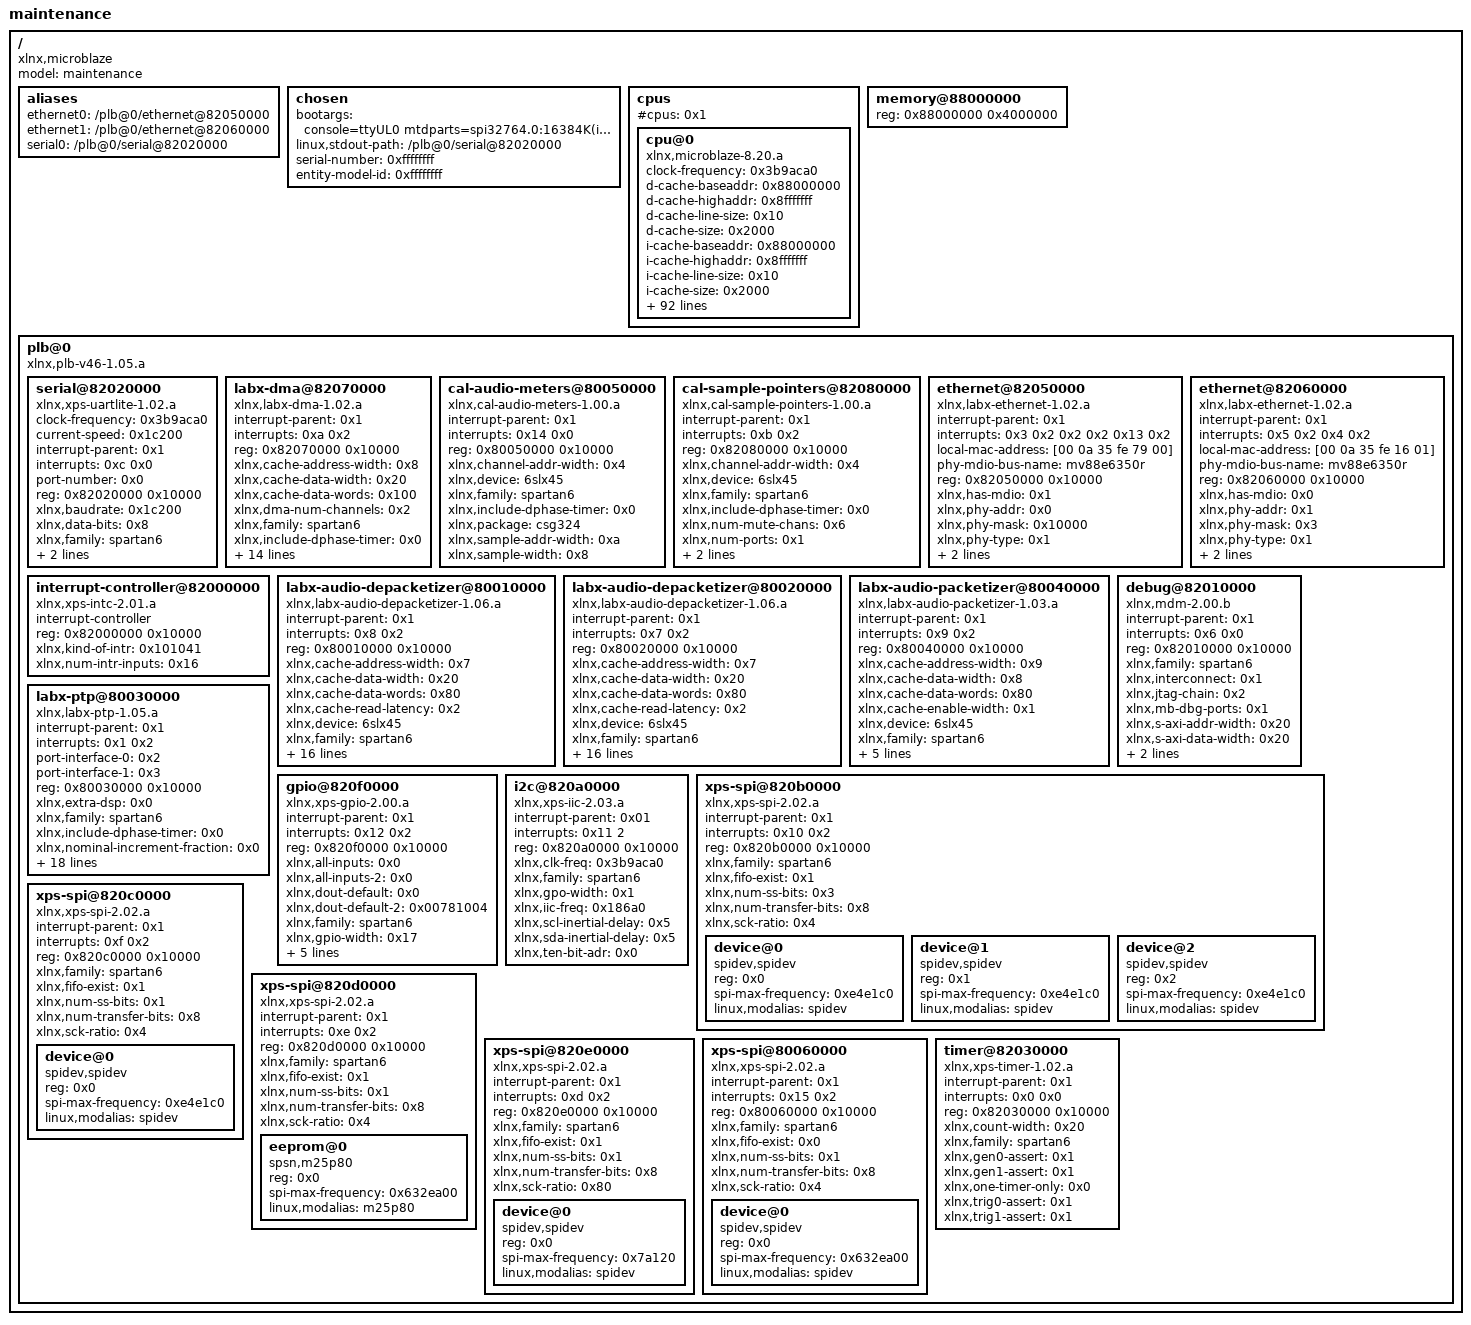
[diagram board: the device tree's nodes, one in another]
/dts-v1/;

/ {
	#address-cells = <0x1>;
	#size-cells = <0x1>;
	compatible = "xlnx,microblaze";
	model = "maintenance";

	aliases {
		ethernet0 = "/plb@0/ethernet@82050000";
		ethernet1 = "/plb@0/ethernet@82060000";
		serial0 = "/plb@0/serial@82020000";
	};

	chosen {
		bootargs = "console=ttyUL0 mtdparts=spi32764.0:16384K(image) root=/dev/ram0 load_ramdisk=1 ramdisk_start=4096 prompt_ramdisk=0 BUTTONS=0x00";
/*
		bootargs = "console=ttyUL0 mtdparts=spi32764.0:2048K(maintfpga),256K(maintboot),256K(maintfdt),1536K(maintimage),1024K(maintrootfs),768K(maintromfs),2048K(maintsettingsfs),256K(bootenv),2048K(fpga),256K(boot),256K(fdt),1536K(image),1024K(rootfs),1024K(romfs),2048K(settingsfs) root=mtd4 rootfstype=romfs init=/bin/init";
*/
		linux,stdout-path = "/plb@0/serial@82020000";
		serial-number=<0xffffffff>;
		entity-model-id=<0xffffffff>;
	};

	cpus {
		#address-cells = <0x1>;
		#cpus = <0x1>;
		#size-cells = <0x0>;

		cpu@0 {
			clock-frequency = <0x3b9aca0>;
			compatible = "xlnx,microblaze-8.20.a";
			d-cache-baseaddr = <0x88000000>;
			d-cache-highaddr = <0x8fffffff>;
			d-cache-line-size = <0x10>;
			d-cache-size = <0x2000>;
			device_type = "cpu";
			i-cache-baseaddr = <0x88000000>;
			i-cache-highaddr = <0x8fffffff>;
			i-cache-line-size = <0x10>;
			i-cache-size = <0x2000>;
			model = "microblaze,8.20.a";
			reg = <0x0>;
			timebase-frequency = <0x3b9aca0>;
			xlnx,addr-tag-bits = <0xe>;
			xlnx,allow-dcache-wr = <0x1>;
			xlnx,allow-icache-wr = <0x1>;
			xlnx,archiver = [30 00];
			xlnx,area-optimized = <0x0>;
			xlnx,avoid-primitives = <0x0>;
			xlnx,branch-target-cache-size = <0x0>;
			xlnx,cache-byte-size = <0x2000>;
			xlnx,compiler = [30 00];
			xlnx,compiler-flags = [30 00];
			xlnx,core-clock-freq-hz = <0x5f5e100>;
			xlnx,d-axi = <0x0>;
			xlnx,d-lmb = <0x1>;
			xlnx,d-plb = <0x1>;
			xlnx,data-size = <0x20>;
			xlnx,dcache-addr-tag = <0xe>;
			xlnx,dcache-always-used = <0x1>;
			xlnx,dcache-byte-size = <0x2000>;
			xlnx,dcache-data-width = <0x0>;
			xlnx,dcache-force-tag-lutram = <0x0>;
			xlnx,dcache-interface = <0x0>;
			xlnx,dcache-line-len = <0x4>;
			xlnx,dcache-use-fsl = <0x1>;
			xlnx,dcache-use-writeback = <0x0>;
			xlnx,dcache-victims = <0x0>;
			xlnx,debug-enabled = <0x1>;
			xlnx,div-zero-exception = <0x1>;
			xlnx,dynamic-bus-sizing = <0x1>;
			xlnx,ecc-use-ce-exception = <0x0>;
			xlnx,edge-is-positive = <0x1>;
			xlnx,endianness = <0x0>;
			xlnx,extra-compiler-flags = [30 00];
			xlnx,family = "spartan6";
			xlnx,fault-tolerant = <0x0>;
			xlnx,fpu-exception = <0x0>;
			xlnx,freq = <0x3b9aca0>;
			xlnx,fsl-data-size = <0x20>;
			xlnx,fsl-exception = <0x0>;
			xlnx,fsl-links = <0x1>;
			xlnx,i-axi = <0x0>;
			xlnx,i-lmb = <0x1>;
			xlnx,i-plb = <0x1>;
			xlnx,icache-always-used = <0x1>;
			xlnx,icache-data-width = <0x0>;
			xlnx,icache-force-tag-lutram = <0x0>;
			xlnx,icache-interface = <0x0>;
			xlnx,icache-line-len = <0x4>;
			xlnx,icache-streams = <0x0>;
			xlnx,icache-use-fsl = <0x1>;
			xlnx,icache-victims = <0x0>;
			xlnx,ill-opcode-exception = <0x1>;
			xlnx,instance = "microblaze_0";
			xlnx,interconnect = <0x1>;
			xlnx,interrupt-is-edge = <0x0>;
			xlnx,lockstep-slave = <0x0>;
			xlnx,mmu-dtlb-size = <0x4>;
			xlnx,mmu-itlb-size = <0x2>;
			xlnx,mmu-privileged-instr = <0x0>;
			xlnx,mmu-tlb-access = <0x3>;
			xlnx,mmu-zones = <0x10>;
			xlnx,multiplier = "false";
			xlnx,number-of-pc-brk = <0x1>;
			xlnx,number-of-rd-addr-brk = <0x0>;
			xlnx,number-of-wr-addr-brk = <0x0>;
			xlnx,opcode-0x0-illegal = <0x1>;
			xlnx,optimization = <0x0>;
			xlnx,pvr = <0x0>;
			xlnx,pvr-user1 = <0x0>;
			xlnx,pvr-user2 = <0x0>;
			xlnx,reset-msr = <0x0>;
			xlnx,sco = <0x0>;
			xlnx,stream-interconnect = <0x0>;
			xlnx,unaligned-exceptions = <0x1>;
			xlnx,use-barrel = <0x1>;
			xlnx,use-branch-target-cache = <0x0>;
			xlnx,use-dcache = <0x1>;
			xlnx,use-div = <0x1>;
			xlnx,use-ext-brk = <0x1>;
			xlnx,use-ext-nm-brk = <0x1>;
			xlnx,use-extended-fsl-instr = <0x0>;
			xlnx,use-fpu = <0x0>;
			xlnx,use-hw-mul = <0x1>;
			xlnx,use-icache = <0x1>;
			xlnx,use-interrupt = <0x1>;
			xlnx,use-mmu = <0x0>;
			xlnx,use-msr-instr = <0x1>;
			xlnx,use-pcmp-instr = <0x1>;
			xlnx,use-stack-protection = <0x0>;
			xlnx,xmdstub-peripheral = "false";
		};
	};

	memory@88000000 {
		device_type = "memory";
		reg = <0x88000000 0x4000000>;
	};

	plb@0 {
		#address-cells = <0x1>;
		#size-cells = <0x1>;
		compatible = "xlnx,plb-v46-1.05.a", "xlnx,plb-v46-1.00.a", "simple-bus";
		ranges;

		serial@82020000 {
			clock-frequency = <0x3b9aca0>;
			compatible = "xlnx,xps-uartlite-1.02.a", "xlnx,xps-uartlite-1.00.a";
			current-speed = <0x1c200>;
			device_type = "serial";
			interrupt-parent = <0x1>;
			interrupts = <0xc 0x0>;
			port-number = <0x0>;
			reg = <0x82020000 0x10000>;
			xlnx,baudrate = <0x1c200>;
			xlnx,data-bits = <0x8>;
			xlnx,family = "spartan6";
			xlnx,odd-parity = <0x1>;
			xlnx,use-parity = <0x0>;
		};

		labx-dma@82070000 {
			compatible = "xlnx,labx-dma-1.02.a";
			interrupt-parent = <0x1>;
			interrupts = <0xa 0x2>;
			reg = <0x82070000 0x10000>;
			xlnx,cache-address-width = <0x8>;
			xlnx,cache-data-width = <0x20>;
			xlnx,cache-data-words = <0x100>;
			xlnx,dma-num-channels = <0x2>;
			xlnx,family = "spartan6";
			xlnx,include-dphase-timer = <0x0>;
			xlnx,interface-type = "DMA_NPI";
			xlnx,internal-params = <0x1>;
			xlnx,microcode-words = <0x400>;
			xlnx,mplb-awidth = <0x20>;
			xlnx,mplb-clk-period-ps = <0x2710>;
			xlnx,mplb-dwidth = <0x80>;
			xlnx,mplb-native-dwidth = <0x20>;
			xlnx,mplb-p2p = <0x0>;
			xlnx,mplb-smallest-slave = <0x20>;
			xlnx,num-cache-interfaces = <0x2>;
			xlnx,num-param-interfaces = <0x2>;
			xlnx,param-address-width = <0x9>;
			xlnx,param-words = <0x200>;
			xlnx,parameter-interlock-fifo = <0x1>;
		};

		cal-audio-meters@80050000 {
			compatible = "xlnx,cal-audio-meters-1.00.a";
			interrupt-parent = <0x1>;
			interrupts = <0x14 0x0>;
			reg = <0x80050000 0x10000>;
			xlnx,channel-addr-width = <0x4>;
			xlnx,device = "6slx45";
			xlnx,family = "spartan6";
			xlnx,include-dphase-timer = <0x0>;
			xlnx,package = "csg324";
			xlnx,sample-addr-width = <0xa>;
			xlnx,sample-width = <0x8>;
		};

		cal-sample-pointers@82080000 {
			compatible = "xlnx,cal-sample-pointers-1.00.a";
			interrupt-parent = <0x1>;
			interrupts = <0xb 0x2>;
			reg = <0x82080000 0x10000>;
			xlnx,channel-addr-width = <0x4>;
			xlnx,device = "6slx45";
			xlnx,family = "spartan6";
			xlnx,include-dphase-timer = <0x0>;
			xlnx,num-mute-chans = <0x6>;
			xlnx,num-ports = <0x1>;
			xlnx,package = "csg324";
			xlnx,sample-addr-width = <0x8>;
		};

		ethernet@82050000 {
			compatible = "xlnx,labx-ethernet-1.02.a";
			device_type = "network";
			interrupt-parent = <0x1>;
			interrupts = <0x3 0x2 0x2 0x2 0x13 0x2>;
			local-mac-address = [00 0a 35 fe 79 00];
			phy-mdio-bus-name = "mv88e6350r";
			reg = <0x82050000 0x10000>;
			xlnx,has-mdio = <0x1>;
			xlnx,phy-addr = <0x0>;
			xlnx,phy-mask = <0x10000>;
			xlnx,phy-type = <0x1>;
			xlnx,rxcsum = <0x0>;
			xlnx,txcsum = <0x0>;
			linux,phandle = <0x2>;
		};

		ethernet@82060000 {
			compatible = "xlnx,labx-ethernet-1.02.a";
			device_type = "network";
			interrupt-parent = <0x1>;
			interrupts = <0x5 0x2 0x4 0x2>;
			local-mac-address = [00 0a 35 fe 16 01];
			phy-mdio-bus-name = "mv88e6350r";
			reg = <0x82060000 0x10000>;
			xlnx,has-mdio = <0x0>;
			xlnx,phy-addr = <0x1>;
			xlnx,phy-mask = <0x3>;
			xlnx,phy-type = <0x1>;
			xlnx,rxcsum = <0x0>;
			xlnx,txcsum = <0x0>;
			linux,phandle = <0x3>;
		};

		interrupt-controller@82000000 {
			#interrupt-cells = <0x2>;
			compatible = "xlnx,xps-intc-2.01.a", "xlnx,xps-intc-1.00.a";
			interrupt-controller;
			reg = <0x82000000 0x10000>;
			xlnx,kind-of-intr = <0x101041>;
			xlnx,num-intr-inputs = <0x16>;
			linux,phandle = <0x1>;
		};

		labx-audio-depacketizer@80010000 {
			compatible = "xlnx,labx-audio-depacketizer-1.06.a";
			interrupt-parent = <0x1>;
			interrupts = <0x8 0x2>;
			reg = <0x80010000 0x10000>;
			xlnx,cache-address-width = <0x7>;
			xlnx,cache-data-width = <0x20>;
			xlnx,cache-data-words = <0x80>;
			xlnx,cache-read-latency = <0x2>;
			xlnx,device = "6slx45";
			xlnx,family = "spartan6";
			xlnx,has-suppress-inputs = <0x0>;
			xlnx,include-dphase-timer = <0x0>;
			xlnx,interface-type = "CACHE_RAM";
			xlnx,is-mcr-host = <0x1>;
			xlnx,mcb-data-width = <0x20>;
			xlnx,mplb-awidth = <0x20>;
			xlnx,mplb-clk-period-ps = <0x2710>;
			xlnx,mplb-dwidth = <0x80>;
			xlnx,mplb-native-dwidth = <0x20>;
			xlnx,mplb-p2p = <0x0>;
			xlnx,mplb-smallest-slave = <0x20>;
			xlnx,npi-data-width = <0x20>;
			xlnx,num-clock-domains = <0x1>;
			xlnx,num-streams = <0x4>;
			xlnx,package = "csg324";
			xlnx,param-address-width = <0x9>;
		};

		labx-audio-depacketizer@80020000 {
			compatible = "xlnx,labx-audio-depacketizer-1.06.a";
			interrupt-parent = <0x1>;
			interrupts = <0x7 0x2>;
			reg = <0x80020000 0x10000>;
			xlnx,cache-address-width = <0x7>;
			xlnx,cache-data-width = <0x20>;
			xlnx,cache-data-words = <0x80>;
			xlnx,cache-read-latency = <0x2>;
			xlnx,device = "6slx45";
			xlnx,family = "spartan6";
			xlnx,has-suppress-inputs = <0x0>;
			xlnx,include-dphase-timer = <0x0>;
			xlnx,interface-type = "CACHE_RAM";
			xlnx,is-mcr-host = <0x1>;
			xlnx,mcb-data-width = <0x20>;
			xlnx,mplb-awidth = <0x20>;
			xlnx,mplb-clk-period-ps = <0x2710>;
			xlnx,mplb-dwidth = <0x80>;
			xlnx,mplb-native-dwidth = <0x20>;
			xlnx,mplb-p2p = <0x0>;
			xlnx,mplb-smallest-slave = <0x20>;
			xlnx,npi-data-width = <0x20>;
			xlnx,num-clock-domains = <0x1>;
			xlnx,num-streams = <0x4>;
			xlnx,package = "csg324";
			xlnx,param-address-width = <0x9>;
		};

		labx-audio-packetizer@80040000 {
			compatible = "xlnx,labx-audio-packetizer-1.03.a";
			interrupt-parent = <0x1>;
			interrupts = <0x9 0x2>;
			reg = <0x80040000 0x10000>;
			xlnx,cache-address-width = <0x9>;
			xlnx,cache-data-width = <0x8>;
			xlnx,cache-data-words = <0x80>;
			xlnx,cache-enable-width = <0x1>;
			xlnx,device = "6slx45";
			xlnx,family = "spartan6";
			xlnx,has-internal-cache-ram = <0x1>;
			xlnx,include-dphase-timer = <0x0>;
			xlnx,is-dual-headed = <0x1>;
			xlnx,num-clock-domains = <0x1>;
			xlnx,package = "csg324";
		};

		debug@82010000 {
			compatible = "xlnx,mdm-2.00.b";
			interrupt-parent = <0x1>;
			interrupts = <0x6 0x0>;
			reg = <0x82010000 0x10000>;
			xlnx,family = "spartan6";
			xlnx,interconnect = <0x1>;
			xlnx,jtag-chain = <0x2>;
			xlnx,mb-dbg-ports = <0x1>;
			xlnx,s-axi-addr-width = <0x20>;
			xlnx,s-axi-data-width = <0x20>;
			xlnx,s-axi-protocol = "AXI4LITE";
			xlnx,use-uart = <0x1>;
		};

		labx-ptp@80030000 {
			compatible = "xlnx,labx-ptp-1.05.a";
			interrupt-parent = <0x1>;
			interrupts = <0x1 0x2>;
			port-interface-0 = <0x2>;
			port-interface-1 = <0x3>;
			reg = <0x80030000 0x10000>;
			xlnx,extra-dsp = <0x0>;
			xlnx,family = "spartan6";
			xlnx,include-dphase-timer = <0x0>;
			xlnx,nominal-increment-fraction = <0x0>;
			xlnx,nominal-increment-mantissa = <0x8>;
			xlnx,num-ports = <0x2>;
			xlnx,phy-mac-rx-delay = <0x500>;
			xlnx,phy-mac-tx-delay = <0x500>;
			xlnx,port-interface-0 = "eth0";
			xlnx,port-interface-1 = "eth1";
			xlnx,port-interface-2 = "Invalid";
			xlnx,port-interface-3 = "Invalid";
			xlnx,port-interface-4 = "Invalid";
			xlnx,port-interface-5 = "Invalid";
			xlnx,port-interface-6 = "Invalid";
			xlnx,port-interface-7 = "Invalid";
			xlnx,port-width = <0x8>;
			xlnx,rtc-d-coefficient = <0x0>;
			xlnx,rtc-i-coefficient = <0x0>;
			xlnx,rtc-p-coefficient = <0x0>;
			xlnx,timer-divider = <0x271>;
			xlnx,timer-prescaler = <0x3e8>;
		};

		gpio@820f0000 {
			compatible = "xlnx,xps-gpio-2.00.a", "xlnx,xps-gpio-1.00.a";
			interrupt-parent = <0x1>;
			interrupts = <0x12 0x2>;
			reg = <0x820f0000 0x10000>;
			xlnx,all-inputs = <0x0>;
			xlnx,all-inputs-2 = <0x0>;
			xlnx,dout-default = <0x0>;
			xlnx,dout-default-2 = <0x00781004>;
			xlnx,family = "spartan6";
			xlnx,gpio-width = <0x17>;
			xlnx,gpio2-width = <0x17>;
			xlnx,interrupt-present = <0x1>;
			xlnx,is-dual = <0x1>;
			xlnx,tri-default = <0x784002>;
			xlnx,tri-default-2 = <0x1e7f8>;
		};

		i2c@820a0000 {
			compatible = "xlnx,xps-iic-2.03.a", "xlnx,xps-iic-2.00.a";
			interrupt-parent = <0x01>;
			interrupts = < 0x11 2 >;
			reg = <0x820a0000 0x10000>;
			xlnx,clk-freq = <0x3b9aca0>;
			xlnx,family = "spartan6";
			xlnx,gpo-width = <0x1>;
			xlnx,iic-freq = <0x186a0>;
			xlnx,scl-inertial-delay = <0x5>;
			xlnx,sda-inertial-delay = <0x5>;
			xlnx,ten-bit-adr = <0x0>;
		};

		xps-spi@820b0000 {
			compatible = "xlnx,xps-spi-2.02.a", "xlnx,xps-spi-2.00.a";
			interrupt-parent = <0x1>;
			interrupts = <0x10 0x2>;
			reg = <0x820b0000 0x10000>;
			xlnx,family = "spartan6";
			xlnx,fifo-exist = <0x1>;
			xlnx,num-ss-bits = <0x3>;
			xlnx,num-transfer-bits = <0x8>;
			xlnx,sck-ratio = <0x4>;

			device@0 {
				compatible = "spidev,spidev";
				reg = <0x0>;
				spi-max-frequency = <0xe4e1c0>;
				linux,modalias = "spidev";
			};

			device@1 {
				compatible = "spidev,spidev";
				reg = <0x1>;
				spi-max-frequency = <0xe4e1c0>;
				linux,modalias = "spidev";
			};

			device@2 {
				compatible = "spidev,spidev";
				reg = <0x2>;
				spi-max-frequency = <0xe4e1c0>;
				linux,modalias = "spidev";
			};
		};

		xps-spi@820c0000 {
			compatible = "xlnx,xps-spi-2.02.a", "xlnx,xps-spi-2.00.a";
			interrupt-parent = <0x1>;
			interrupts = <0xf 0x2>;
			reg = <0x820c0000 0x10000>;
			xlnx,family = "spartan6";
			xlnx,fifo-exist = <0x1>;
			xlnx,num-ss-bits = <0x1>;
			xlnx,num-transfer-bits = <0x8>;
			xlnx,sck-ratio = <0x4>;

			device@0 {
				compatible = "spidev,spidev";
				reg = <0x0>;
				spi-max-frequency = <0xe4e1c0>;
				linux,modalias = "spidev";
			};
		};

		xps-spi@820d0000 {
			compatible = "xlnx,xps-spi-2.02.a", "xlnx,xps-spi-2.00.a";
			interrupt-parent = <0x1>;
			interrupts = <0xe 0x2>;
			reg = <0x820d0000 0x10000>;
			xlnx,family = "spartan6";
			xlnx,fifo-exist = <0x1>;
			xlnx,num-ss-bits = <0x1>;
			xlnx,num-transfer-bits = <0x8>;
			xlnx,sck-ratio = <0x4>;

			eeprom@0 {
				compatible = "spsn,m25p80";
				reg = <0x0>;
				spi-max-frequency = <0x632ea00>;
				linux,modalias = "m25p80";
			};
		};

		xps-spi@820e0000 {
			compatible = "xlnx,xps-spi-2.02.a", "xlnx,xps-spi-2.00.a";
			interrupt-parent = <0x1>;
			interrupts = <0xd 0x2>;
			reg = <0x820e0000 0x10000>;
			xlnx,family = "spartan6";
			xlnx,fifo-exist = <0x1>;
			xlnx,num-ss-bits = <0x1>;
			xlnx,num-transfer-bits = <0x8>;
			xlnx,sck-ratio = <0x80>;

			device@0 {
				compatible = "spidev,spidev";
				reg = <0x0>;
				spi-max-frequency = <0x7a120>;
				linux,modalias = "spidev";
			};
		};

		xps-spi@80060000 {
			compatible = "xlnx,xps-spi-2.02.a", "xlnx,xps-spi-2.00.a";
			interrupt-parent = <0x1>;
			interrupts = <0x15 0x2>;
			reg = <0x80060000 0x10000>;
			xlnx,family = "spartan6";
			xlnx,fifo-exist = <0x0>;
			xlnx,num-ss-bits = <0x1>;
			xlnx,num-transfer-bits = <0x8>;
			xlnx,sck-ratio = <0x4>;

			device@0 {
				compatible = "spidev,spidev";
				reg = <0x0>;
				spi-max-frequency = <0x632ea00>;
				linux,modalias = "spidev";
			};
		};

		timer@82030000 {
			compatible = "xlnx,xps-timer-1.02.a", "xlnx,xps-timer-1.00.a";
			interrupt-parent = <0x1>;
			interrupts = <0x0 0x0>;
			reg = <0x82030000 0x10000>;
			xlnx,count-width = <0x20>;
			xlnx,family = "spartan6";
			xlnx,gen0-assert = <0x1>;
			xlnx,gen1-assert = <0x1>;
			xlnx,one-timer-only = <0x0>;
			xlnx,trig0-assert = <0x1>;
			xlnx,trig1-assert = <0x1>;
		};
	};
};
